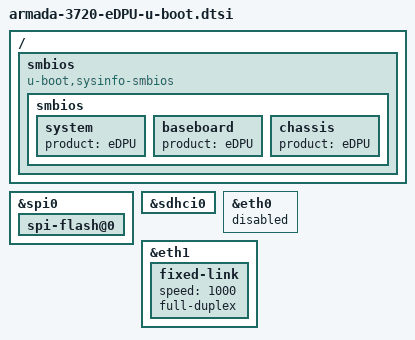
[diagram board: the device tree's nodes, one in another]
// SPDX-License-Identifier: GPL-2.0+

/ {
	smbios {
		compatible = "u-boot,sysinfo-smbios";

		smbios {
			system {
				product = "eDPU";
			};

			baseboard {
				product = "eDPU";
			};

			chassis {
				product = "eDPU";
			};
		};
	};
};

&spi0 {
	u-boot,dm-all;

	spi-flash@0 {
		u-boot,dm-all;
	};
};

&sdhci0 {
	u-boot,dm-all;
};

&eth0 {
	/* G.hn does not work without additional configuration */
	status = "disabled";
};

&eth1 {
	fixed-link {
		speed = <1000>;
		full-duplex;
	};
};
